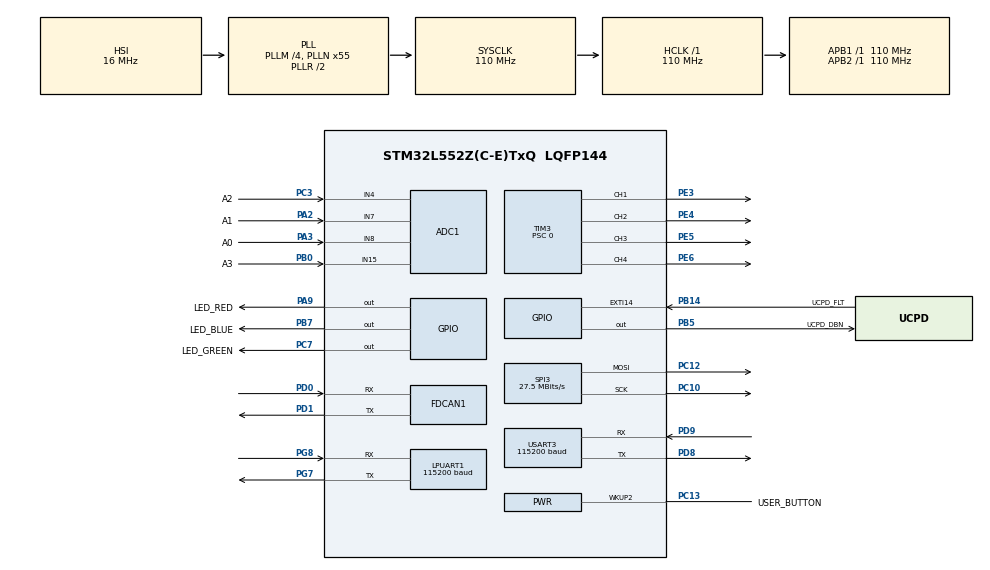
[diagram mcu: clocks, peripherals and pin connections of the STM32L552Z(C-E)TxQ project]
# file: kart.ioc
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ADC1.Channel-10\#ChannelRegularConversion=ADC_CHANNEL_TEMPSENSOR
ADC1.Channel-11\#ChannelRegularConversion=ADC_CHANNEL_4
ADC1.Channel-6\#ChannelRegularConversion=ADC_CHANNEL_8
ADC1.Channel-7\#ChannelRegularConversion=ADC_CHANNEL_7
ADC1.Channel-8\#ChannelRegularConversion=ADC_CHANNEL_4
ADC1.Channel-9\#ChannelRegularConversion=ADC_CHANNEL_15
ADC1.ClockPrescaler=ADC_CLOCK_ASYNC_DIV4
ADC1.ContinuousConvMode=ENABLE
ADC1.DMAContinuousRequests=ENABLE
ADC1.DiscontinuousConvMode=DISABLE
ADC1.EOCSelection=ADC_EOC_SEQ_CONV
ADC1.NbrOfConversion=6
ADC1.NbrOfConversionFlag=1
ADC1.OffsetNumber-10\#ChannelRegularConversion=ADC_OFFSET_NONE
ADC1.OffsetNumber-11\#ChannelRegularConversion=ADC_OFFSET_NONE
ADC1.OffsetNumber-6\#ChannelRegularConversion=ADC_OFFSET_NONE
ADC1.OffsetNumber-7\#ChannelRegularConversion=ADC_OFFSET_NONE
ADC1.OffsetNumber-8\#ChannelRegularConversion=ADC_OFFSET_NONE
ADC1.OffsetNumber-9\#ChannelRegularConversion=ADC_OFFSET_NONE
ADC1.Overrun=ADC_OVR_DATA_OVERWRITTEN
ADC1.Rank-10\#ChannelRegularConversion=5
ADC1.Rank-11\#ChannelRegularConversion=6
ADC1.Rank-6\#ChannelRegularConversion=1
ADC1.Rank-7\#ChannelRegularConversion=2
ADC1.Rank-8\#ChannelRegularConversion=3
ADC1.Rank-9\#ChannelRegularConversion=4
ADC1.SamplingTime-10\#ChannelRegularConversion=ADC_SAMPLETIME_92CYCLES_5
ADC1.SamplingTime-11\#ChannelRegularConversion=ADC_SAMPLETIME_2CYCLES_5
ADC1.SamplingTime-6\#ChannelRegularConversion=ADC_SAMPLETIME_92CYCLES_5
ADC1.SamplingTime-7\#ChannelRegularConversion=ADC_SAMPLETIME_92CYCLES_5
ADC1.SamplingTime-8\#ChannelRegularConversion=ADC_SAMPLETIME_92CYCLES_5
ADC1.SamplingTime-9\#ChannelRegularConversion=ADC_SAMPLETIME_92CYCLES_5
ADC1.master=1
Dma.ADC1.0.Channel_PRIV_NPRIV=DMA_CHANNEL_NPRIV_DISABLE
Dma.ADC1.0.Direction=DMA_PERIPH_TO_MEMORY
Dma.ADC1.0.EventEnable=DISABLE
Dma.ADC1.0.Instance=DMA1_Channel1
Dma.ADC1.0.MemDataAlignment=DMA_MDATAALIGN_WORD
Dma.ADC1.0.MemInc=DMA_MINC_ENABLE
Dma.ADC1.0.Mode=DMA_CIRCULAR
Dma.ADC1.0.PeriphDataAlignment=DMA_PDATAALIGN_WORD
Dma.ADC1.0.PeriphInc=DMA_PINC_DISABLE
Dma.ADC1.0.Polarity=HAL_DMAMUX_REQ_GEN_RISING
Dma.ADC1.0.Priority=DMA_PRIORITY_LOW
Dma.ADC1.0.RequestNumber=1
Dma.ADC1.0.SignalID=NONE
Dma.ADC1.0.SyncEnable=DISABLE
Dma.ADC1.0.SyncPolarity=HAL_DMAMUX_SYNC_NO_EVENT
Dma.ADC1.0.SyncRequestNumber=1
Dma.ADC1.0.SyncSignalID=NONE
Dma.Request0=ADC1
FDCAN1.ClockDivider=FDCAN_CLOCK_DIV1
FDCAN1.DataPrescaler=5
FDCAN1.DataSyncJumpWidth=16
FDCAN1.DataTimeSeg1=11
FDCAN1.DataTimeSeg2=4
FDCAN1.NominalPrescaler=2
FDCAN1.NominalSyncJumpWidth=55
FDCAN1.NominalTimeSeg1=40
FDCAN1.NominalTimeSeg2=14
FREERTOS.Tasks01=defaultTask,24,128,StartDefaultTask,Default,NULL,Dynamic,NULL,NULL
LPUART1.BaudRate=115200
LPUART1.Parity=UART_PARITY_NONE
LPUART1.WordLength=UART_WORDLENGTH_8B
Mcu.Family=STM32L5
Mcu.Name=STM32L552Z(C-E)TxQ
Mcu.Package=LQFP144
Mcu.TrustZone=disable
Mcu.UserConstants=TIM3_MAX_DUTY,11000
NVIC.DMA1_Channel1_IRQn=true\:5\:0\:false\:false\:true\:true\:false\:true
NVIC.FDCAN1_IT0_IRQn=true\:5\:0\:false\:false\:true\:true\:true\:true
NVIC.FDCAN1_IT1_IRQn=true\:5\:0\:false\:false\:true\:true\:true\:true
NVIC.LPUART1_IRQn=true\:5\:0\:false\:false\:true\:true\:true\:true
NVIC.PriorityGroup=NVIC_PRIORITYGROUP_3
NVIC.USART3_IRQn=true\:5\:0\:false\:false\:true\:true\:true\:true
PA11.Signal=USB_DM
PA13\ (JTMS/SWDIO).Mode=Trace_Asynchronous_SW
PA13\ (JTMS/SWDIO).Signal=DEBUG_JTMS-SWDIO
PA14\ (JTCK/SWCLK).Mode=Trace_Asynchronous_SW
PA14\ (JTCK/SWCLK).Signal=DEBUG_JTCK-SWCLK
PA2.GPIO_Label=A1
PA2.Signal=ADCx_IN7
PA3.GPIO_Label=A0
PA3.Signal=ADCx_IN8
PA5.Signal=S_TIM2_CH1
PA9.GPIO_Label=LED_RED
PA9.Signal=GPIO_Output
PB0.GPIO_Label=A3
PB0.Signal=ADCx_IN15
PB14.GPIO_Label=UCPD_FLT
PB14.Signal=GPXTI14
PB3\ (JTDO/TRACESWO).Mode=Trace_Asynchronous_SW
PB3\ (JTDO/TRACESWO).Signal=DEBUG_JTDO-SWO
PB5.GPIO_Label=UCPD_DBN
PB5.Signal=GPIO_Output
PB7.GPIO_Label=LED_BLUE
PB7.Signal=GPIO_Output
PC10.Mode=TX_Only_Simplex_Unidirect_Master
PC10.Signal=SPI3_SCK
PC12.Mode=TX_Only_Simplex_Unidirect_Master
PC12.Signal=SPI3_MOSI
PC13.GPIO_Label=USER_BUTTON
PC13.Mode=WakeUp1
PC13.Signal=PWR_WKUP2
PC14-OSC32_IN\ (PC14).Mode=LSE-External-Oscillator
PC14-OSC32_IN\ (PC14).Signal=RCC_OSC32_IN
PC15-OSC32_OUT\ (PC15).Mode=LSE-External-Oscillator
PC15-OSC32_OUT\ (PC15).Signal=RCC_OSC32_OUT
PC2.Signal=ADCx_IN3
PC3.GPIO_Label=A2
PC3.Signal=ADCx_IN4
PC7.GPIO_Label=LED_GREEN
PC7.Signal=GPIO_Output
PD0.Mode=FDCAN_Activate
PD0.Signal=FDCAN1_RX
PD1.Mode=FDCAN_Activate
PD1.Signal=FDCAN1_TX
PD8.Mode=Asynchronous
PD8.Signal=USART3_TX
PD9.Mode=Asynchronous
PD9.Signal=USART3_RX
PE3.Signal=S_TIM3_CH1
PE4.Signal=S_TIM3_CH2
PE5.Signal=S_TIM3_CH3
PE6.Signal=S_TIM3_CH4
PG7.Mode=Asynchronous
PG7.Signal=LPUART1_TX
PG8.Mode=Asynchronous
PG8.Signal=LPUART1_RX
ProjectManager.HeapSize=0x200
ProjectManager.StackSize=0x400
ProjectManager.TargetToolchain=EWARM V8.32
RCC.ADCCLockSelection=RCC_ADCCLKSOURCE_SYSCLK
RCC.ADCFreq_Value=110000000
RCC.AHBFreq_Value=110000000
RCC.APB1Freq_Value=110000000
RCC.APB1TimFreq_Value=110000000
RCC.APB2Freq_Value=110000000
RCC.APB2TimFreq_Value=110000000
RCC.CK48CLockSelection=RCC_USBCLKSOURCE_HSI48
RCC.CortexFreq_Value=110000000
RCC.HCLKFreq_Value=110000000
RCC.HSE_VALUE=8000000
RCC.HSI48_VALUE=48000000
RCC.HSI_VALUE=16000000
RCC.MSI_VALUE=4000000
RCC.PLLM=4
RCC.PLLN=55
RCC.PLLSAI1N=24
RCC.PLLSAI1Source=RCC_PLLSAI1SOURCE_HSI
RCC.PLLSAI2Source=RCC_PLLSAI2SOURCE_HSI
RCC.PLLSourceVirtual=RCC_PLLSOURCE_HSI
RCC.RTCClockSelection=RCC_RTCCLKSOURCE_LSE
RCC.SYSCLKFreq_VALUE=110000000
RCC.SYSCLKSource=RCC_SYSCLKSOURCE_PLLCLK
RCC.USBFreq_Value=48000000
RCC.VCOOutputFreq_Value=220000000
SH.ADCx_IN15.0=ADC1_IN15,IN15-Single-Ended
SH.ADCx_IN3.0=ADC1_IN3
SH.ADCx_IN4.0=ADC1_IN4,IN4-Single-Ended
SH.ADCx_IN7.0=ADC1_IN7,IN7-Single-Ended
SH.ADCx_IN8.0=ADC1_IN8,IN8-Single-Ended
SH.S_TIM2_CH1.0=TIM2_CH1
SH.S_TIM3_CH1.0=TIM3_CH1,PWM Generation1 CH1
SH.S_TIM3_CH2.0=TIM3_CH2,PWM Generation2 CH2
SH.S_TIM3_CH3.0=TIM3_CH3,PWM Generation3 CH3
SH.S_TIM3_CH4.0=TIM3_CH4,PWM Generation4 CH4
SPI3.BaudRatePrescaler=SPI_BAUDRATEPRESCALER_4
SPI3.CalculateBaudRate=27.5 MBits/s
SPI3.Direction=SPI_DIRECTION_2LINES
SPI3.Mode=SPI_MODE_MASTER
SPI3.VirtualType=VM_MASTER
TIM3.AutoReloadPreload=TIM_AUTORELOAD_PRELOAD_DISABLE
TIM3.Channel-PWM\ Generation1\ CH1=TIM_CHANNEL_1
TIM3.Channel-PWM\ Generation2\ CH2=TIM_CHANNEL_2
TIM3.Channel-PWM\ Generation3\ CH3=TIM_CHANNEL_3
TIM3.Channel-PWM\ Generation4\ CH4=TIM_CHANNEL_4
TIM3.OCPolarity_1=TIM_OCPOLARITY_HIGH
TIM3.OCPolarity_2=TIM_OCPOLARITY_HIGH
TIM3.OCPolarity_3=TIM_OCPOLARITY_HIGH
TIM3.OCPolarity_4=TIM_OCPOLARITY_HIGH
TIM3.Period=TIM3_MAX_DUTY
TIM3.Prescaler=0
TIM3.Pulse-PWM\ Generation1\ CH1=TIM3_MAX_DUTY/2
TIM3.Pulse-PWM\ Generation2\ CH2=TIM3_MAX_DUTY/2
TIM3.Pulse-PWM\ Generation3\ CH3=TIM3_MAX_DUTY/2
TIM3.Pulse-PWM\ Generation4\ CH4=TIM3_MAX_DUTY/2
USART3.BaudRate=115200
USART3.FIFOMode=FIFOMODE_DISABLE
USART3.VirtualMode-Asynchronous=VM_ASYNC
VP_ADC1_TempSens_Input.Mode=IN-TempSens
VP_FREERTOS_VS_CMSIS_V2.Mode=CMSIS_V2
VP_PWR_VS_DBSignals.Mode=DisableDeadBatterySignals
VP_PWR_VS_SECSignals.Mode=Security/Privilege
VP_RTC_VS_RTC_Activate.Mode=RTC_Enabled
VP_TIM3_VS_ClockSourceINT.Mode=Internal
board=NUCLEO-L552ZE-Q

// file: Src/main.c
/* USER CODE BEGIN Header */
/**
 ******************************************************************************
 * @file           : main.c
 * @brief          : Main program body
 ******************************************************************************
 * @attention
 *
 * <h2><center>&copy; Copyright (c) 2021 STMicroelectronics.
 * All rights reserved.</center></h2>
 *
 * This software component is licensed by ST under Ultimate Liberty license
 * SLA0044, the "License"; You may not use this file except in compliance with
 * the License. You may obtain a copy of the License at:
 *                             www.st.com/SLA0044
 *
 ******************************************************************************
 */
/* USER CODE END Header */
#include "main.h"
#include "cmsis_os.h"

/* USER CODE BEGIN Includes */
#include "system/system_api.h"

/* USER CODE END Includes */

ADC_HandleTypeDef hadc1;
DMA_HandleTypeDef hdma_adc1;

FDCAN_HandleTypeDef hfdcan1;

UART_HandleTypeDef hlpuart1;
UART_HandleTypeDef huart3;

RTC_HandleTypeDef hrtc;

SPI_HandleTypeDef hspi3;

TIM_HandleTypeDef htim3;

/* Definitions for defaultTask */
osThreadId_t defaultTaskHandle;
const osThreadAttr_t defaultTask_attributes = {
  .name = "defaultTask",
  .priority = (osPriority_t) osPriorityNormal,
  .stack_size = 128 * 4
};

void SystemClock_Config(void);
static void MX_GPIO_Init(void);
static void MX_ADC1_Init(void);
static void MX_RTC_Init(void);
static void MX_SPI3_Init(void);
static void MX_DMA_Init(void);
static void MX_TIM3_Init(void);
static void MX_FDCAN1_Init(void);
static void MX_USART3_UART_Init(void);
static void MX_LPUART1_UART_Init(void);
void StartDefaultTask(void *argument);

int main(void)
{

  /* MCU Configuration--------------------------------------------------------*/

  /* Reset of all peripherals, Initializes the Flash interface and the Systick. */
  HAL_Init();

  /* Configure the system clock */
  SystemClock_Config();

  /* USER CODE BEGIN SysInit */
    MX_DMA_Init();

  /* USER CODE END SysInit */

  /* Initialize all configured peripherals */
  MX_GPIO_Init();
  MX_ADC1_Init();
  MX_RTC_Init();
  MX_SPI3_Init();
  MX_DMA_Init();
  MX_TIM3_Init();
  MX_FDCAN1_Init();
  MX_USART3_UART_Init();
  MX_LPUART1_UART_Init();

  /* Init scheduler */
  osKernelInitialize();

  /* Create the thread(s) */
  /* creation of defaultTask */
  defaultTaskHandle = osThreadNew(StartDefaultTask, NULL, &defaultTask_attributes);

  /* USER CODE BEGIN RTOS_THREADS */
    system_init();

  /* USER CODE END RTOS_THREADS */

  /* Start scheduler */
  osKernelStart();

  /* We should never get here as control is now taken by the scheduler */
  /* Infinite loop */
    while (1)
    {

    }
}

void SystemClock_Config(void)
{
  RCC_OscInitTypeDef RCC_OscInitStruct = {0};
  RCC_ClkInitTypeDef RCC_ClkInitStruct = {0};

  /** Configure the main internal regulator output voltage
  */
  if (HAL_PWREx_ControlVoltageScaling(PWR_REGULATOR_VOLTAGE_SCALE0) != HAL_OK)
  {
    Error_Handler();
  }
  /** Configure LSE Drive Capability
  */
  HAL_PWR_EnableBkUpAccess();
  __HAL_RCC_LSEDRIVE_CONFIG(RCC_LSEDRIVE_LOW);
  /** Initializes the RCC Oscillators according to the specified parameters
  * in the RCC_OscInitTypeDef structure.
  */
  RCC_OscInitStruct.OscillatorType = RCC_OSCILLATORTYPE_HSI|RCC_OSCILLATORTYPE_LSE;
  RCC_OscInitStruct.LSEState = RCC_LSE_ON;
  RCC_OscInitStruct.HSIState = RCC_HSI_ON;
  RCC_OscInitStruct.HSICalibrationValue = RCC_HSICALIBRATION_DEFAULT;
  RCC_OscInitStruct.PLL.PLLState = RCC_PLL_ON;
  RCC_OscInitStruct.PLL.PLLSource = RCC_PLLSOURCE_HSI;
  RCC_OscInitStruct.PLL.PLLM = 4;
  RCC_OscInitStruct.PLL.PLLN = 55;
  RCC_OscInitStruct.PLL.PLLP = RCC_PLLP_DIV7;
  RCC_OscInitStruct.PLL.PLLQ = RCC_PLLQ_DIV2;
  RCC_OscInitStruct.PLL.PLLR = RCC_PLLR_DIV2;
  if (HAL_RCC_OscConfig(&RCC_OscInitStruct) != HAL_OK)
  {
    Error_Handler();
  }
  /** Initializes the CPU, AHB and APB buses clocks
  */
  RCC_ClkInitStruct.ClockType = RCC_CLOCKTYPE_HCLK|RCC_CLOCKTYPE_SYSCLK
                              |RCC_CLOCKTYPE_PCLK1|RCC_CLOCKTYPE_PCLK2;
  RCC_ClkInitStruct.SYSCLKSource = RCC_SYSCLKSOURCE_PLLCLK;
  RCC_ClkInitStruct.AHBCLKDivider = RCC_SYSCLK_DIV1;
  RCC_ClkInitStruct.APB1CLKDivider = RCC_HCLK_DIV1;
  RCC_ClkInitStruct.APB2CLKDivider = RCC_HCLK_DIV1;

  if (HAL_RCC_ClockConfig(&RCC_ClkInitStruct, FLASH_LATENCY_5) != HAL_OK)
  {
    Error_Handler();
  }
}

static void MX_ADC1_Init(void)
{

  ADC_MultiModeTypeDef multimode = {0};
  ADC_ChannelConfTypeDef sConfig = {0};

  /** Common config
  */
  hadc1.Instance = ADC1;
  hadc1.Init.ClockPrescaler = ADC_CLOCK_ASYNC_DIV4;
  hadc1.Init.Resolution = ADC_RESOLUTION_12B;
  hadc1.Init.DataAlign = ADC_DATAALIGN_RIGHT;
  hadc1.Init.ScanConvMode = ADC_SCAN_ENABLE;
  hadc1.Init.EOCSelection = ADC_EOC_SEQ_CONV;
  hadc1.Init.LowPowerAutoWait = DISABLE;
  hadc1.Init.ContinuousConvMode = ENABLE;
  hadc1.Init.NbrOfConversion = 6;
  hadc1.Init.DiscontinuousConvMode = DISABLE;
  hadc1.Init.ExternalTrigConv = ADC_SOFTWARE_START;
  hadc1.Init.ExternalTrigConvEdge = ADC_EXTERNALTRIGCONVEDGE_NONE;
  hadc1.Init.DMAContinuousRequests = ENABLE;
  hadc1.Init.Overrun = ADC_OVR_DATA_OVERWRITTEN;
  hadc1.Init.OversamplingMode = DISABLE;
  if (HAL_ADC_Init(&hadc1) != HAL_OK)
  {
    Error_Handler();
  }
  /** Configure the ADC multi-mode
  */
  multimode.Mode = ADC_MODE_INDEPENDENT;
  if (HAL_ADCEx_MultiModeConfigChannel(&hadc1, &multimode) != HAL_OK)
  {
    Error_Handler();
  }
  /** Configure Regular Channel
  */
  sConfig.Channel = ADC_CHANNEL_8;
  sConfig.Rank = ADC_REGULAR_RANK_1;
  sConfig.SamplingTime = ADC_SAMPLETIME_92CYCLES_5;
  sConfig.SingleDiff = ADC_SINGLE_ENDED;
  sConfig.OffsetNumber = ADC_OFFSET_NONE;
  sConfig.Offset = 0;
  if (HAL_ADC_ConfigChannel(&hadc1, &sConfig) != HAL_OK)
  {
    Error_Handler();
  }
  /** Configure Regular Channel
  */
  sConfig.Channel = ADC_CHANNEL_7;
  sConfig.Rank = ADC_REGULAR_RANK_2;
  if (HAL_ADC_ConfigChannel(&hadc1, &sConfig) != HAL_OK)
  {
    Error_Handler();
  }
  /** Configure Regular Channel
  */
  sConfig.Channel = ADC_CHANNEL_4;
  sConfig.Rank = ADC_REGULAR_RANK_3;
  if (HAL_ADC_ConfigChannel(&hadc1, &sConfig) != HAL_OK)
  {
    Error_Handler();
  }
  /** Configure Regular Channel
  */
  sConfig.Channel = ADC_CHANNEL_15;
  sConfig.Rank = ADC_REGULAR_RANK_4;
  if (HAL_ADC_ConfigChannel(&hadc1, &sConfig) != HAL_OK)
  {
    Error_Handler();
  }
  /** Configure Regular Channel
  */
  sConfig.Channel = ADC_CHANNEL_TEMPSENSOR;
  sConfig.Rank = ADC_REGULAR_RANK_5;
  if (HAL_ADC_ConfigChannel(&hadc1, &sConfig) != HAL_OK)
  {
    Error_Handler();
  }
  /** Configure Regular Channel
  */
  sConfig.Channel = ADC_CHANNEL_4;
  sConfig.Rank = ADC_REGULAR_RANK_6;
  sConfig.SamplingTime = ADC_SAMPLETIME_2CYCLES_5;
  if (HAL_ADC_ConfigChannel(&hadc1, &sConfig) != HAL_OK)
  {
    Error_Handler();
  }

}

static void MX_FDCAN1_Init(void)
{

  hfdcan1.Instance = FDCAN1;
  hfdcan1.Init.ClockDivider = FDCAN_CLOCK_DIV1;
  hfdcan1.Init.FrameFormat = FDCAN_FRAME_CLASSIC;
  hfdcan1.Init.Mode = FDCAN_MODE_NORMAL;
  hfdcan1.Init.AutoRetransmission = DISABLE;
  hfdcan1.Init.TransmitPause = DISABLE;
  hfdcan1.Init.ProtocolException = DISABLE;
  hfdcan1.Init.NominalPrescaler = 2;
  hfdcan1.Init.NominalSyncJumpWidth = 55;
  hfdcan1.Init.NominalTimeSeg1 = 40;
  hfdcan1.Init.NominalTimeSeg2 = 14;
  hfdcan1.Init.DataPrescaler = 5;
  hfdcan1.Init.DataSyncJumpWidth = 16;
  hfdcan1.Init.DataTimeSeg1 = 11;
  hfdcan1.Init.DataTimeSeg2 = 4;
  hfdcan1.Init.StdFiltersNbr = 0;
  hfdcan1.Init.ExtFiltersNbr = 0;
  hfdcan1.Init.TxFifoQueueMode = FDCAN_TX_FIFO_OPERATION;
  if (HAL_FDCAN_Init(&hfdcan1) != HAL_OK)
  {
    Error_Handler();
  }

}

static void MX_LPUART1_UART_Init(void)
{

  hlpuart1.Instance = LPUART1;
  hlpuart1.Init.BaudRate = 115200;
  hlpuart1.Init.WordLength = UART_WORDLENGTH_8B;
  hlpuart1.Init.StopBits = UART_STOPBITS_1;
  hlpuart1.Init.Parity = UART_PARITY_NONE;
  hlpuart1.Init.Mode = UART_MODE_TX_RX;
  hlpuart1.Init.HwFlowCtl = UART_HWCONTROL_NONE;
  hlpuart1.Init.OneBitSampling = UART_ONE_BIT_SAMPLE_DISABLE;
  hlpuart1.Init.ClockPrescaler = UART_PRESCALER_DIV1;
  hlpuart1.AdvancedInit.AdvFeatureInit = UART_ADVFEATURE_NO_INIT;
  hlpuart1.FifoMode = UART_FIFOMODE_DISABLE;
  if (HAL_UART_Init(&hlpuart1) != HAL_OK)
  {
    Error_Handler();
  }
  if (HAL_UARTEx_SetTxFifoThreshold(&hlpuart1, UART_TXFIFO_THRESHOLD_1_8) != HAL_OK)
  {
    Error_Handler();
  }
  if (HAL_UARTEx_SetRxFifoThreshold(&hlpuart1, UART_RXFIFO_THRESHOLD_1_8) != HAL_OK)
  {
    Error_Handler();
  }
  if (HAL_UARTEx_DisableFifoMode(&hlpuart1) != HAL_OK)
  {
    Error_Handler();
  }

}

static void MX_USART3_UART_Init(void)
{

  huart3.Instance = USART3;
  huart3.Init.BaudRate = 115200;
  huart3.Init.WordLength = UART_WORDLENGTH_8B;
  huart3.Init.StopBits = UART_STOPBITS_1;
  huart3.Init.Parity = UART_PARITY_NONE;
  huart3.Init.Mode = UART_MODE_TX_RX;
  huart3.Init.HwFlowCtl = UART_HWCONTROL_NONE;
  huart3.Init.OverSampling = UART_OVERSAMPLING_16;
  huart3.Init.OneBitSampling = UART_ONE_BIT_SAMPLE_DISABLE;
  huart3.Init.ClockPrescaler = UART_PRESCALER_DIV1;
  huart3.AdvancedInit.AdvFeatureInit = UART_ADVFEATURE_NO_INIT;
  if (HAL_UART_Init(&huart3) != HAL_OK)
  {
    Error_Handler();
  }
  if (HAL_UARTEx_SetTxFifoThreshold(&huart3, UART_TXFIFO_THRESHOLD_1_8) != HAL_OK)
  {
    Error_Handler();
  }
  if (HAL_UARTEx_SetRxFifoThreshold(&huart3, UART_RXFIFO_THRESHOLD_1_8) != HAL_OK)
  {
    Error_Handler();
  }
  if (HAL_UARTEx_DisableFifoMode(&huart3) != HAL_OK)
  {
    Error_Handler();
  }

}

static void MX_RTC_Init(void)
{

  RTC_PrivilegeStateTypeDef privilegeState = {0};

  /** Initialize RTC Only
  */
  hrtc.Instance = RTC;
  hrtc.Init.HourFormat = RTC_HOURFORMAT_24;
  hrtc.Init.AsynchPrediv = 127;
  hrtc.Init.SynchPrediv = 255;
  hrtc.Init.OutPut = RTC_OUTPUT_DISABLE;
  hrtc.Init.OutPutRemap = RTC_OUTPUT_REMAP_NONE;
  hrtc.Init.OutPutPolarity = RTC_OUTPUT_POLARITY_HIGH;
  hrtc.Init.OutPutType = RTC_OUTPUT_TYPE_OPENDRAIN;
  hrtc.Init.OutPutPullUp = RTC_OUTPUT_PULLUP_NONE;
  if (HAL_RTC_Init(&hrtc) != HAL_OK)
  {
    Error_Handler();
  }
  privilegeState.rtcPrivilegeFull = RTC_PRIVILEGE_FULL_NO;
  privilegeState.backupRegisterPrivZone = RTC_PRIVILEGE_BKUP_ZONE_NONE;
  privilegeState.backupRegisterStartZone2 = RTC_BKP_DR0;
  privilegeState.backupRegisterStartZone3 = RTC_BKP_DR0;
  if (HAL_RTCEx_PrivilegeModeSet(&hrtc, &privilegeState) != HAL_OK)
  {
    Error_Handler();
  }

}

static void MX_SPI3_Init(void)
{

  /* SPI3 parameter configuration*/
  hspi3.Instance = SPI3;
  hspi3.Init.Mode = SPI_MODE_MASTER;
  hspi3.Init.Direction = SPI_DIRECTION_2LINES;
  hspi3.Init.DataSize = SPI_DATASIZE_4BIT;
  hspi3.Init.CLKPolarity = SPI_POLARITY_LOW;
  hspi3.Init.CLKPhase = SPI_PHASE_1EDGE;
  hspi3.Init.NSS = SPI_NSS_SOFT;
  hspi3.Init.BaudRatePrescaler = SPI_BAUDRATEPRESCALER_4;
  hspi3.Init.FirstBit = SPI_FIRSTBIT_MSB;
  hspi3.Init.TIMode = SPI_TIMODE_DISABLE;
  hspi3.Init.CRCCalculation = SPI_CRCCALCULATION_DISABLE;
  hspi3.Init.CRCPolynomial = 7;
  hspi3.Init.CRCLength = SPI_CRC_LENGTH_DATASIZE;
  hspi3.Init.NSSPMode = SPI_NSS_PULSE_ENABLE;
  if (HAL_SPI_Init(&hspi3) != HAL_OK)
  {
    Error_Handler();
  }

}

static void MX_TIM3_Init(void)
{

  TIM_ClockConfigTypeDef sClockSourceConfig = {0};
  TIM_MasterConfigTypeDef sMasterConfig = {0};
  TIM_OC_InitTypeDef sConfigOC = {0};

  htim3.Instance = TIM3;
  htim3.Init.Prescaler = 0;
  htim3.Init.CounterMode = TIM_COUNTERMODE_UP;
  htim3.Init.Period = TIM3_MAX_DUTY;
  htim3.Init.ClockDivision = TIM_CLOCKDIVISION_DIV1;
  htim3.Init.AutoReloadPreload = TIM_AUTORELOAD_PRELOAD_DISABLE;
  if (HAL_TIM_Base_Init(&htim3) != HAL_OK)
  {
    Error_Handler();
  }
  sClockSourceConfig.ClockSource = TIM_CLOCKSOURCE_INTERNAL;
  if (HAL_TIM_ConfigClockSource(&htim3, &sClockSourceConfig) != HAL_OK)
  {
    Error_Handler();
  }
  if (HAL_TIM_PWM_Init(&htim3) != HAL_OK)
  {
    Error_Handler();
  }
  sMasterConfig.MasterOutputTrigger = TIM_TRGO_RESET;
  sMasterConfig.MasterSlaveMode = TIM_MASTERSLAVEMODE_DISABLE;
  if (HAL_TIMEx_MasterConfigSynchronization(&htim3, &sMasterConfig) != HAL_OK)
  {
    Error_Handler();
  }
  sConfigOC.OCMode = TIM_OCMODE_PWM1;
  sConfigOC.Pulse = TIM3_MAX_DUTY/2;
  sConfigOC.OCPolarity = TIM_OCPOLARITY_HIGH;
  sConfigOC.OCFastMode = TIM_OCFAST_DISABLE;
  if (HAL_TIM_PWM_ConfigChannel(&htim3, &sConfigOC, TIM_CHANNEL_1) != HAL_OK)
  {
    Error_Handler();
  }
  if (HAL_TIM_PWM_ConfigChannel(&htim3, &sConfigOC, TIM_CHANNEL_2) != HAL_OK)
  {
    Error_Handler();
  }
  if (HAL_TIM_PWM_ConfigChannel(&htim3, &sConfigOC, TIM_CHANNEL_3) != HAL_OK)
  {
    Error_Handler();
  }
  if (HAL_TIM_PWM_ConfigChannel(&htim3, &sConfigOC, TIM_CHANNEL_4) != HAL_OK)
  {
    Error_Handler();
  }
  HAL_TIM_MspPostInit(&htim3);

}

static void MX_DMA_Init(void)
{

  /* DMA controller clock enable */
  __HAL_RCC_DMAMUX1_CLK_ENABLE();
  __HAL_RCC_DMA1_CLK_ENABLE();

  /* DMA interrupt init */
  /* DMA1_Channel1_IRQn interrupt configuration */
  HAL_NVIC_SetPriority(DMA1_Channel1_IRQn, 5, 0);
  HAL_NVIC_EnableIRQ(DMA1_Channel1_IRQn);

}

static void MX_GPIO_Init(void)
{
  GPIO_InitTypeDef GPIO_InitStruct = {0};

  /* GPIO Ports Clock Enable */
  __HAL_RCC_GPIOE_CLK_ENABLE();
  __HAL_RCC_GPIOC_CLK_ENABLE();
  __HAL_RCC_GPIOA_CLK_ENABLE();
  __HAL_RCC_GPIOB_CLK_ENABLE();
  __HAL_RCC_GPIOD_CLK_ENABLE();
  __HAL_RCC_GPIOG_CLK_ENABLE();
  HAL_PWREx_EnableVddIO2();

  /*Configure GPIO pin Output Level */
  HAL_GPIO_WritePin(LED_GREEN_GPIO_Port, LED_GREEN_Pin, GPIO_PIN_RESET);

  /*Configure GPIO pin Output Level */
  HAL_GPIO_WritePin(LED_RED_GPIO_Port, LED_RED_Pin, GPIO_PIN_RESET);

  /*Configure GPIO pin Output Level */
  HAL_GPIO_WritePin(GPIOB, UCPD_DBN_Pin|LED_BLUE_Pin, GPIO_PIN_RESET);

  /*Configure GPIO pin : PA5 */
  GPIO_InitStruct.Pin = GPIO_PIN_5;
  GPIO_InitStruct.Mode = GPIO_MODE_AF_PP;
  GPIO_InitStruct.Pull = GPIO_NOPULL;
  GPIO_InitStruct.Speed = GPIO_SPEED_FREQ_LOW;
  GPIO_InitStruct.Alternate = GPIO_AF1_TIM2;
  HAL_GPIO_Init(GPIOA, &GPIO_InitStruct);

  /*Configure GPIO pin : UCPD_FLT_Pin */
  GPIO_InitStruct.Pin = UCPD_FLT_Pin;
  GPIO_InitStruct.Mode = GPIO_MODE_IT_RISING;
  GPIO_InitStruct.Pull = GPIO_NOPULL;
  HAL_GPIO_Init(UCPD_FLT_GPIO_Port, &GPIO_InitStruct);

  /*Configure GPIO pin : LED_GREEN_Pin */
  GPIO_InitStruct.Pin = LED_GREEN_Pin;
  GPIO_InitStruct.Mode = GPIO_MODE_OUTPUT_PP;
  GPIO_InitStruct.Pull = GPIO_NOPULL;
  GPIO_InitStruct.Speed = GPIO_SPEED_FREQ_LOW;
  HAL_GPIO_Init(LED_GREEN_GPIO_Port, &GPIO_InitStruct);

  /*Configure GPIO pin : LED_RED_Pin */
  GPIO_InitStruct.Pin = LED_RED_Pin;
  GPIO_InitStruct.Mode = GPIO_MODE_OUTPUT_PP;
  GPIO_InitStruct.Pull = GPIO_NOPULL;
  GPIO_InitStruct.Speed = GPIO_SPEED_FREQ_LOW;
  HAL_GPIO_Init(LED_RED_GPIO_Port, &GPIO_InitStruct);

  /*Configure GPIO pin : PA11 */
  GPIO_InitStruct.Pin = GPIO_PIN_11;
  GPIO_InitStruct.Mode = GPIO_MODE_AF_PP;
  GPIO_InitStruct.Pull = GPIO_NOPULL;
  GPIO_InitStruct.Speed = GPIO_SPEED_FREQ_LOW;
  GPIO_InitStruct.Alternate = GPIO_AF10_USB;
  HAL_GPIO_Init(GPIOA, &GPIO_InitStruct);

  /*Configure GPIO pins : UCPD_DBN_Pin LED_BLUE_Pin */
  GPIO_InitStruct.Pin = UCPD_DBN_Pin|LED_BLUE_Pin;
  GPIO_InitStruct.Mode = GPIO_MODE_OUTPUT_PP;
  GPIO_InitStruct.Pull = GPIO_NOPULL;
  GPIO_InitStruct.Speed = GPIO_SPEED_FREQ_LOW;
  HAL_GPIO_Init(GPIOB, &GPIO_InitStruct);

}

void StartDefaultTask(void *argument)
{
    for (;;)
    {
        osDelay(1);
    }
}

void Error_Handler(void)
{
    __disable_irq();
    while (1)
    {
    }
}

/************************ (C) COPYRIGHT STMicroelectronics *****END OF FILE****/
